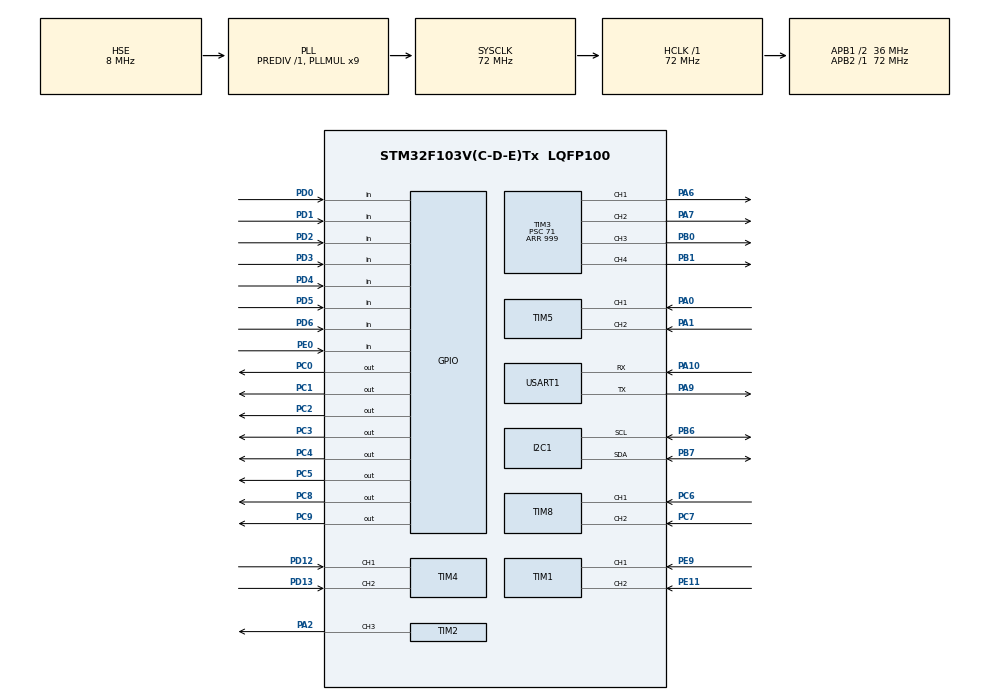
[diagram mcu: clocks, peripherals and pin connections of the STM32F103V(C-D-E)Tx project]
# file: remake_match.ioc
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Mcu.Family=STM32F1
Mcu.Name=STM32F103V(C-D-E)Tx
Mcu.Package=LQFP100
NVIC.I2C1_ER_IRQn=true\:0\:0\:false\:false\:true\:true\:true
NVIC.I2C1_EV_IRQn=true\:0\:0\:false\:false\:true\:true\:true
NVIC.PriorityGroup=NVIC_PRIORITYGROUP_4
NVIC.TIM6_IRQn=true\:2\:0\:true\:false\:true\:true\:true
NVIC.USART1_IRQn=true\:0\:0\:false\:false\:true\:true\:true
OSC_IN.Mode=HSE-External-Oscillator
OSC_IN.Signal=RCC_OSC_IN
OSC_OUT.Mode=HSE-External-Oscillator
OSC_OUT.Signal=RCC_OSC_OUT
PA0-WKUP.Signal=S_TIM5_CH1
PA1.Signal=S_TIM5_CH2
PA10.Mode=Asynchronous
PA10.Signal=USART1_RX
PA13.Mode=Serial_Wire
PA13.Signal=SYS_JTMS-SWDIO
PA14.Mode=Serial_Wire
PA14.Signal=SYS_JTCK-SWCLK
PA2.Signal=S_TIM2_CH3
PA6.Signal=S_TIM3_CH1
PA7.Signal=S_TIM3_CH2
PA9.Mode=Asynchronous
PA9.Signal=USART1_TX
PB0.Signal=S_TIM3_CH3
PB1.Signal=S_TIM3_CH4
PB6.Mode=I2C
PB6.Signal=I2C1_SCL
PB7.Mode=I2C
PB7.Signal=I2C1_SDA
PC0.GPIO_PuPd=GPIO_PULLDOWN
PC0.GPIO_Speed=GPIO_SPEED_FREQ_HIGH
PC0.PinState=GPIO_PIN_RESET
PC0.Signal=GPIO_Output
PC1.GPIO_PuPd=GPIO_PULLDOWN
PC1.GPIO_Speed=GPIO_SPEED_FREQ_HIGH
PC1.PinState=GPIO_PIN_RESET
PC1.Signal=GPIO_Output
PC2.GPIO_PuPd=GPIO_PULLDOWN
PC2.GPIO_Speed=GPIO_SPEED_FREQ_HIGH
PC2.PinState=GPIO_PIN_RESET
PC2.Signal=GPIO_Output
PC3.GPIO_PuPd=GPIO_PULLDOWN
PC3.GPIO_Speed=GPIO_SPEED_FREQ_HIGH
PC3.Signal=GPIO_Output
PC4.GPIO_PuPd=GPIO_PULLDOWN
PC4.GPIO_Speed=GPIO_SPEED_FREQ_HIGH
PC4.Signal=GPIO_Output
PC5.GPIO_PuPd=GPIO_PULLDOWN
PC5.GPIO_Speed=GPIO_SPEED_FREQ_HIGH
PC5.Signal=GPIO_Output
PC6.Signal=S_TIM8_CH1
PC7.Signal=S_TIM8_CH2
PC8.GPIO_PuPd=GPIO_PULLDOWN
PC8.GPIO_Speed=GPIO_SPEED_FREQ_HIGH
PC8.Signal=GPIO_Output
PC9.GPIO_PuPd=GPIO_PULLDOWN
PC9.GPIO_Speed=GPIO_SPEED_FREQ_HIGH
PC9.Signal=GPIO_Output
PD0.GPIO_PuPd=GPIO_PULLDOWN
PD0.Signal=GPIO_Input
PD1.GPIO_PuPd=GPIO_PULLDOWN
PD1.Signal=GPIO_Input
PD12.Signal=S_TIM4_CH1
PD13.Signal=S_TIM4_CH2
PD2.GPIO_PuPd=GPIO_PULLDOWN
PD2.Signal=GPIO_Input
PD3.GPIO_PuPd=GPIO_PULLDOWN
PD3.Signal=GPIO_Input
PD4.GPIO_PuPd=GPIO_PULLDOWN
PD4.Signal=GPIO_Input
PD5.GPIO_PuPd=GPIO_PULLDOWN
PD5.Signal=GPIO_Input
PD6.GPIO_PuPd=GPIO_PULLDOWN
PD6.Signal=GPIO_Input
PE0.GPIO_PuPd=GPIO_PULLDOWN
PE0.Signal=GPIO_Input
PE11.Signal=S_TIM1_CH2
PE9.Signal=S_TIM1_CH1
ProjectManager.HeapSize=0x200
ProjectManager.StackSize=0x400
ProjectManager.TargetToolchain=MDK-ARM V5
RCC.AHBFreq_Value=72000000
RCC.APB1CLKDivider=RCC_HCLK_DIV2
RCC.APB1Freq_Value=36000000
RCC.APB1TimFreq_Value=72000000
RCC.APB2Freq_Value=72000000
RCC.APB2TimFreq_Value=72000000
RCC.HCLKFreq_Value=72000000
RCC.PLLMUL=RCC_PLL_MUL9
RCC.PLLSourceVirtual=RCC_PLLSOURCE_HSE
RCC.SYSCLKFreq_VALUE=72000000
RCC.SYSCLKSource=RCC_SYSCLKSOURCE_PLLCLK
RCC.USBFreq_Value=72000000
SH.S_TIM1_CH1.0=TIM1_CH1,Encoder_Interface
SH.S_TIM1_CH2.0=TIM1_CH2,Encoder_Interface
SH.S_TIM2_CH3.0=TIM2_CH3,PWM Generation3 CH3
SH.S_TIM3_CH1.0=TIM3_CH1,PWM Generation1 CH1
SH.S_TIM3_CH2.0=TIM3_CH2,PWM Generation2 CH2
SH.S_TIM3_CH3.0=TIM3_CH3,PWM Generation3 CH3
SH.S_TIM3_CH4.0=TIM3_CH4,PWM Generation4 CH4
SH.S_TIM4_CH1.0=TIM4_CH1,Encoder_Interface
SH.S_TIM4_CH2.0=TIM4_CH2,Encoder_Interface
SH.S_TIM5_CH1.0=TIM5_CH1,Encoder_Interface
SH.S_TIM5_CH2.0=TIM5_CH2,Encoder_Interface
SH.S_TIM8_CH1.0=TIM8_CH1,Encoder_Interface
SH.S_TIM8_CH2.0=TIM8_CH2,Encoder_Interface
TIM1.EncoderMode=TIM_ENCODERMODE_TI12
TIM2.Channel-PWM\ Generation3\ CH3=TIM_CHANNEL_3
TIM2.Period=19999
TIM2.Prescaler=71
TIM3.Channel-PWM\ Generation1\ CH1=TIM_CHANNEL_1
TIM3.Channel-PWM\ Generation2\ CH2=TIM_CHANNEL_2
TIM3.Channel-PWM\ Generation3\ CH3=TIM_CHANNEL_3
TIM3.Channel-PWM\ Generation4\ CH4=TIM_CHANNEL_4
TIM3.Period=999
TIM3.Prescaler=71
TIM4.EncoderMode=TIM_ENCODERMODE_TI12
TIM5.EncoderMode=TIM_ENCODERMODE_TI12
TIM6.Period=4999
TIM6.Prescaler=71
TIM8.EncoderMode=TIM_ENCODERMODE_TI12
USART1.VirtualMode=VM_ASYNC
VP_TIM6_VS_ClockSourceINT.Mode=Enable_Timer
board=custom

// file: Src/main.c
/* USER CODE BEGIN Header */
/**
  ******************************************************************************
  * @file           : main.c
  * @brief          : Main program body
  ******************************************************************************
  * @attention
  *
  * Copyright (c) 2022 STMicroelectronics.
  * All rights reserved.
  *
  * This software is licensed under terms that can be found in the LICENSE file
  * in the root directory of this software component.
  * If no LICENSE file comes with this software, it is provided AS-IS.
  *
  ******************************************************************************
  */
/* USER CODE END Header */
#include "main.h"
#include "i2c.h"
#include "tim.h"
#include "usart.h"
#include "gpio.h"

/* USER CODE BEGIN Includes */
#include "encoder.h"
#include "pid.h"
#include "mode.h"
#include "chassis.h"
#include "opencv.h"
#include "steering_engine.h"
/* USER CODE END Includes */

void SystemClock_Config(void);

/* USER CODE BEGIN 0 */
//void HAL_UART_RxCpltCallback(UART_HandleTypeDef *huart)
//{
// if(huart->Instance==USART1)
// {
//  if(Rx_data==49)
//	{
//	 Step=3;
//	}
//  HAL_UART_Receive_IT(&huart1,&Rx_data,1);
// }
//}
/* USER CODE END 0 */

int main(void)
{

  /* MCU Configuration--------------------------------------------------------*/

  /* Reset of all peripherals, Initializes the Flash interface and the Systick. */
  HAL_Init();

  /* USER CODE BEGIN Init */
  HAL_UART_Receive_IT(&huart1,&Rx_data,1);
  /* USER CODE END Init */

  /* Configure the system clock */
  SystemClock_Config();

  /* Initialize all configured peripherals */
  MX_GPIO_Init();
  MX_TIM1_Init();
  MX_TIM3_Init();
  MX_TIM4_Init();
  MX_TIM5_Init();
  MX_TIM8_Init();
  MX_TIM2_Init();
  MX_TIM6_Init();
  MX_I2C1_Init();
  MX_USART1_UART_Init();
  /* USER CODE BEGIN 2 */
	HAL_TIM_Base_Start_IT(&htim6);
	Encoder_Init();
	Chassis_Init();
	ALL_Pid_Init();
	Opencv_Init();
	Steering_Engine_Init();
  /* USER CODE END 2 */

  /* Infinite loop */
  while (1)
  {

  }
}

void SystemClock_Config(void)
{
  RCC_OscInitTypeDef RCC_OscInitStruct = {0};
  RCC_ClkInitTypeDef RCC_ClkInitStruct = {0};

  /** Initializes the RCC Oscillators according to the specified parameters
  * in the RCC_OscInitTypeDef structure.
  */
  RCC_OscInitStruct.OscillatorType = RCC_OSCILLATORTYPE_HSE;
  RCC_OscInitStruct.HSEState = RCC_HSE_ON;
  RCC_OscInitStruct.HSEPredivValue = RCC_HSE_PREDIV_DIV1;
  RCC_OscInitStruct.HSIState = RCC_HSI_ON;
  RCC_OscInitStruct.PLL.PLLState = RCC_PLL_ON;
  RCC_OscInitStruct.PLL.PLLSource = RCC_PLLSOURCE_HSE;
  RCC_OscInitStruct.PLL.PLLMUL = RCC_PLL_MUL9;
  if (HAL_RCC_OscConfig(&RCC_OscInitStruct) != HAL_OK)
  {
    Error_Handler();
  }
  /** Initializes the CPU, AHB and APB buses clocks
  */
  RCC_ClkInitStruct.ClockType = RCC_CLOCKTYPE_HCLK|RCC_CLOCKTYPE_SYSCLK
                              |RCC_CLOCKTYPE_PCLK1|RCC_CLOCKTYPE_PCLK2;
  RCC_ClkInitStruct.SYSCLKSource = RCC_SYSCLKSOURCE_PLLCLK;
  RCC_ClkInitStruct.AHBCLKDivider = RCC_SYSCLK_DIV1;
  RCC_ClkInitStruct.APB1CLKDivider = RCC_HCLK_DIV2;
  RCC_ClkInitStruct.APB2CLKDivider = RCC_HCLK_DIV1;

  if (HAL_RCC_ClockConfig(&RCC_ClkInitStruct, FLASH_LATENCY_2) != HAL_OK)
  {
    Error_Handler();
  }
}

void Error_Handler(void)
{
  __disable_irq();
  while (1)
  {
  }
}
